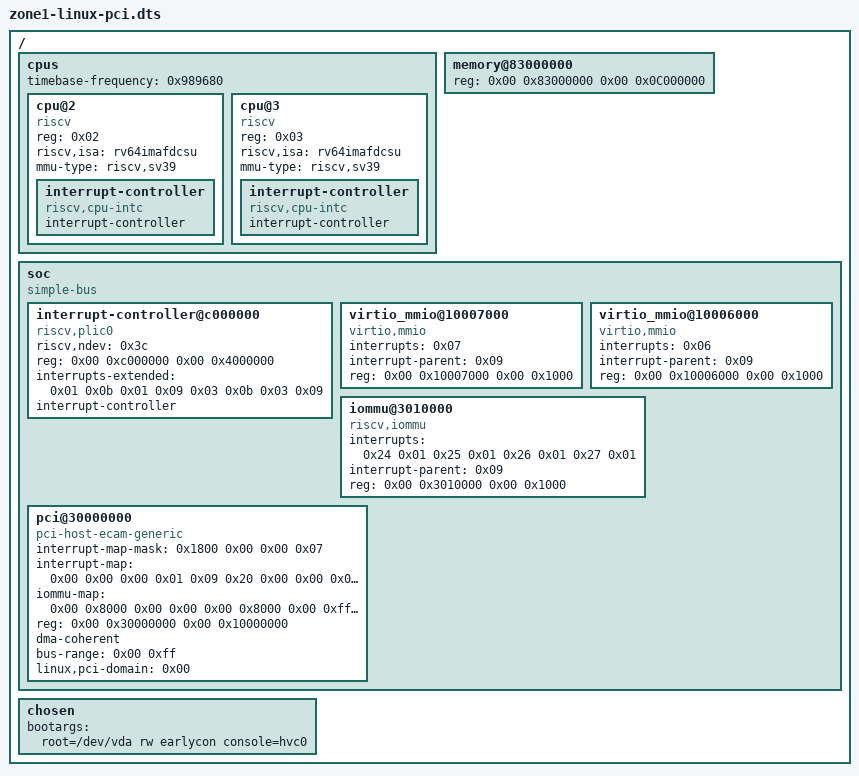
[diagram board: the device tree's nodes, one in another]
/dts-v1/;

/ {
	#address-cells = <0x02>;
	#size-cells = <0x02>;

	cpus {
		#address-cells = <0x01>;
		#size-cells = <0x00>;
		timebase-frequency = <0x989680>;

		cpu@2 {
			device_type = "cpu";
			reg = <0x02>;
			status = "okay";
			compatible = "riscv";
			riscv,isa = "rv64imafdcsu";
			mmu-type = "riscv,sv39";

			interrupt-controller {
				#interrupt-cells = <0x01>;
				interrupt-controller;
				compatible = "riscv,cpu-intc";
				phandle = <0x01>;
			};
		};

		cpu@3 {
			device_type = "cpu";
			reg = <0x03>;
			status = "okay";
			compatible = "riscv";
			riscv,isa = "rv64imafdcsu";
			mmu-type = "riscv,sv39";

			interrupt-controller {
				#interrupt-cells = <0x01>;
				interrupt-controller;
				compatible = "riscv,cpu-intc";
				phandle = <0x03>;
			};
		};
	};

	memory@83000000 {
		device_type = "memory";
		reg = <0x00 0x83000000 0x00 0x0C000000>;
	};

	soc {
		#address-cells = <0x02>;
		#size-cells = <0x02>;
		compatible = "simple-bus";
		ranges;

		interrupt-controller@c000000 {
			riscv,ndev = <0x3c>;
			reg = <0x00 0xc000000 0x00 0x4000000>;
			interrupts-extended = <0x01 0x0b 0x01 0x09 0x03 0x0b 0x03 0x09>;
			interrupt-controller;
			compatible = "riscv,plic0";
			#interrupt-cells = <0x01>;
			phandle = <0x09>;
		};

		virtio_mmio@10007000 {
			interrupts = <0x07>;
			interrupt-parent = <0x09>;
			reg = <0x00 0x10007000 0x00 0x1000>;
			compatible = "virtio,mmio";
		};

		virtio_mmio@10006000 {
			interrupts = <0x06>;
			interrupt-parent = <0x09>;
			reg = <0x00 0x10006000 0x00 0x1000>;
			compatible = "virtio,mmio";
		};

		iommu@3010000 {
			interrupts = <0x24 0x01 0x25 0x01 0x26 0x01 0x27 0x01>;
			interrupt-parent = <0x09>;
			reg = <0x00 0x3010000 0x00 0x1000>;
			phandle = <0x8000>;
			#iommu-cells = <0x01>;
			compatible = "riscv,iommu";
		};
		
        pci@30000000 {
			interrupt-map-mask = <0x1800 0x00 0x00 0x07>;
			interrupt-map = <0x00 0x00 0x00 0x01 0x09 0x20 0x00 0x00 0x00 0x02 0x09 0x21 0x00 0x00 0x00 0x03 0x09 0x22 0x00 0x00 0x00 0x04 0x09 0x23 0x800 0x00 0x00 0x01 0x09 0x21 0x800 0x00 0x00 0x02 0x09 0x22 0x800 0x00 0x00 0x03 0x09 0x23 0x800 0x00 0x00 0x04 0x09 0x20 0x1000 0x00 0x00 0x01 0x09 0x22 0x1000 0x00 0x00 0x02 0x09 0x23 0x1000 0x00 0x00 0x03 0x09 0x20 0x1000 0x00 0x00 0x04 0x09 0x21 0x1800 0x00 0x00 0x01 0x09 0x23 0x1800 0x00 0x00 0x02 0x09 0x20 0x1800 0x00 0x00 0x03 0x09 0x21 0x1800 0x00 0x00 0x04 0x09 0x22>;
			iommu-map = <0x00 0x8000 0x00 0x00 0x00 0x8000 0x00 0xffff>;
			ranges = <0x1000000 0x00 0x00 0x00 0x3000000 0x00 0x10000 0x2000000 0x00 0x40000000 0x00 0x40000000 0x00 0x40000000 0x3000000 0x04 0x00 0x04 0x00 0x04 0x00>;
			reg = <0x00 0x30000000 0x00 0x10000000>;
			dma-coherent;
			bus-range = <0x00 0xff>;
			linux,pci-domain = <0x00>;
			device_type = "pci";
			compatible = "pci-host-ecam-generic";
			#size-cells = <0x02>;
			#interrupt-cells = <0x01>;
			#address-cells = <0x03>;
		};

	};

	chosen {
		bootargs = "root=/dev/vda rw earlycon console=hvc0";
	};
};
